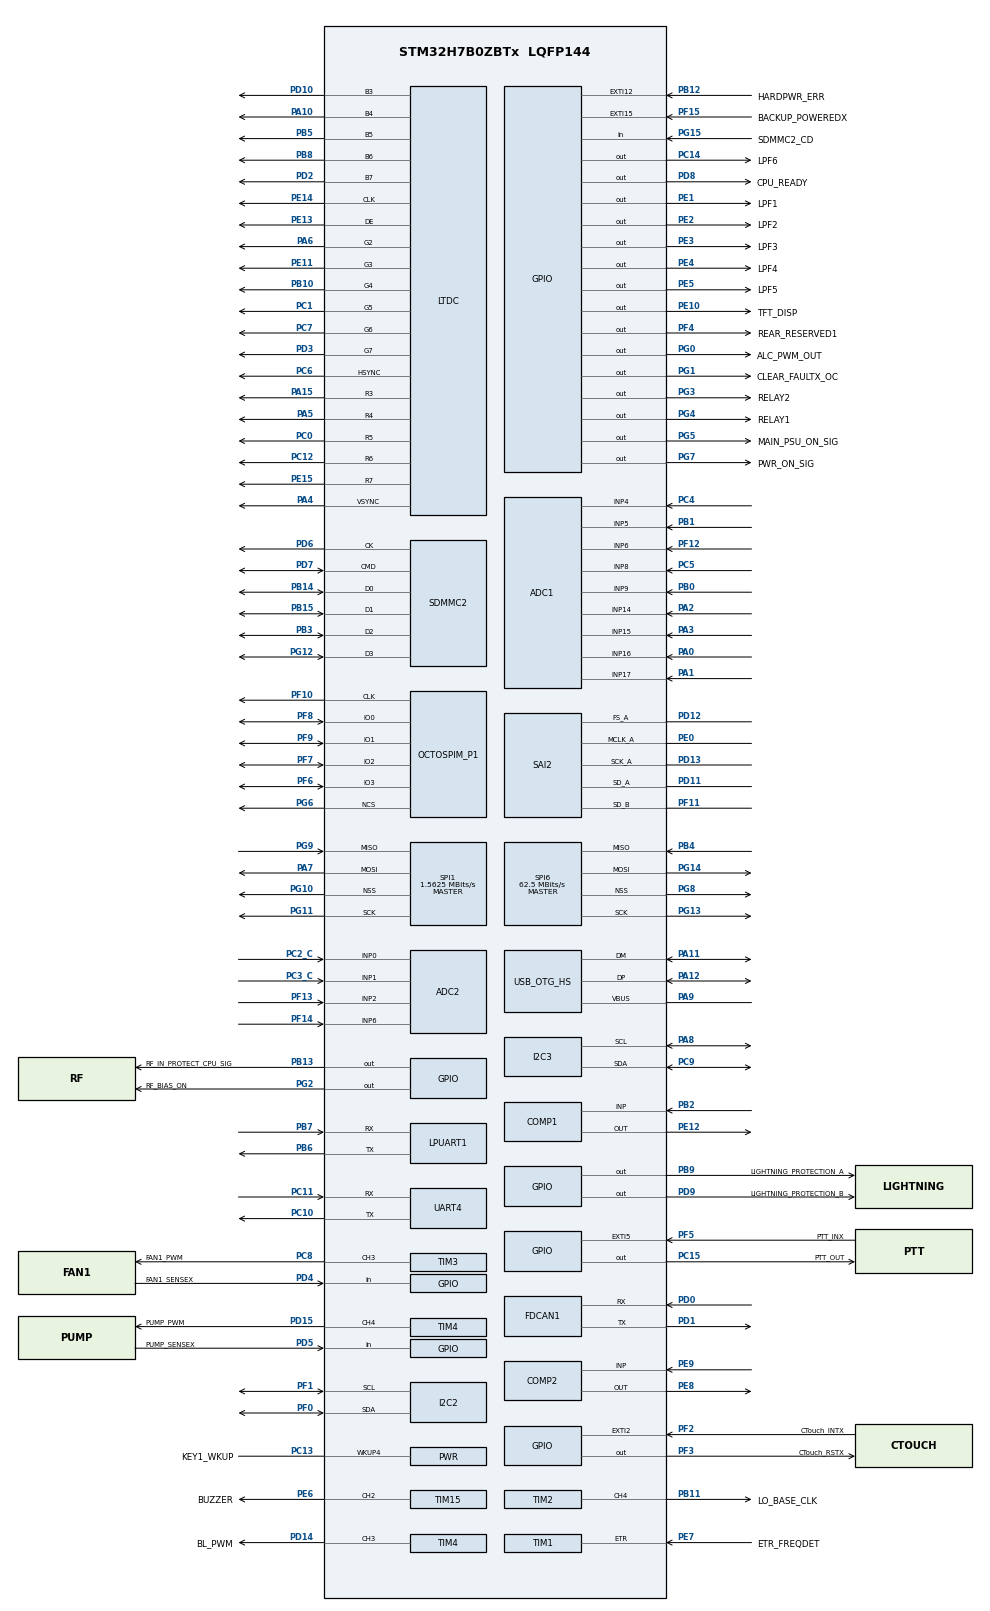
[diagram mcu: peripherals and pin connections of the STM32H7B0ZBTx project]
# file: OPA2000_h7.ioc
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ADC1.AWD1HighThreshold=65532
ADC1.AWD1ITMode=ENABLE
ADC1.AWD2HighThreshold=65532
ADC1.AWD2ITMode=ENABLE
ADC1.AWD3HighThreshold=65532
ADC1.AWD3ITMode=ENABLE
ADC1.AWDChannel-3\#ChannelRegularConversion=ADC_CHANNEL_5
ADC1.AWDChannel-4\#ChannelRegularConversion=ADC_CHANNEL_6
ADC1.Channel-10\#ChannelRegularConversion=ADC_CHANNEL_16
ADC1.Channel-11\#ChannelRegularConversion=ADC_CHANNEL_17
ADC1.Channel-2\#ChannelRegularConversion=ADC_CHANNEL_4
ADC1.Channel-3\#ChannelRegularConversion=ADC_CHANNEL_5
ADC1.Channel-4\#ChannelRegularConversion=ADC_CHANNEL_6
ADC1.Channel-5\#ChannelRegularConversion=ADC_CHANNEL_8
ADC1.Channel-7\#ChannelRegularConversion=ADC_CHANNEL_9
ADC1.Channel-8\#ChannelRegularConversion=ADC_CHANNEL_14
ADC1.Channel-9\#ChannelRegularConversion=ADC_CHANNEL_15
ADC1.ClockPrescaler=ADC_CLOCK_ASYNC_DIV1
ADC1.ContinuousConvMode=ENABLE
ADC1.ConversionDataManagement=ADC_CONVERSIONDATA_DMA_CIRCULAR
ADC1.EOCSelection=ADC_EOC_SEQ_CONV
ADC1.EnableAnalogWatchDog1=true
ADC1.EnableAnalogWatchDog2=true
ADC1.EnableAnalogWatchDog3=true
ADC1.EnableInjectedConversion=DISABLE
ADC1.MonitoredBy-10\#ChannelRegularConversion=__NULL
ADC1.MonitoredBy-11\#ChannelRegularConversion=__NULL
ADC1.MonitoredBy-3\#ChannelRegularConversion=ADC_ANALOGWATCHDOG_2
ADC1.MonitoredBy-4\#ChannelRegularConversion=ADC_ANALOGWATCHDOG_3
ADC1.MonitoredBy-8\#ChannelRegularConversion=__NULL
ADC1.MonitoredBy-9\#ChannelRegularConversion=__NULL
ADC1.NbrOfConversion=9
ADC1.NbrOfConversionFlag=1
ADC1.OffsetNumber-10\#ChannelRegularConversion=ADC_OFFSET_NONE
ADC1.OffsetNumber-11\#ChannelRegularConversion=ADC_OFFSET_NONE
ADC1.OffsetNumber-2\#ChannelRegularConversion=ADC_OFFSET_NONE
ADC1.OffsetNumber-3\#ChannelRegularConversion=ADC_OFFSET_NONE
ADC1.OffsetNumber-4\#ChannelRegularConversion=ADC_OFFSET_NONE
ADC1.OffsetNumber-5\#ChannelRegularConversion=ADC_OFFSET_NONE
ADC1.OffsetNumber-7\#ChannelRegularConversion=ADC_OFFSET_NONE
ADC1.OffsetNumber-8\#ChannelRegularConversion=ADC_OFFSET_NONE
ADC1.OffsetNumber-9\#ChannelRegularConversion=ADC_OFFSET_NONE
ADC1.OffsetSignedSaturation-10\#ChannelRegularConversion=DISABLE
ADC1.OffsetSignedSaturation-11\#ChannelRegularConversion=DISABLE
ADC1.OffsetSignedSaturation-2\#ChannelRegularConversion=DISABLE
ADC1.OffsetSignedSaturation-3\#ChannelRegularConversion=DISABLE
ADC1.OffsetSignedSaturation-4\#ChannelRegularConversion=DISABLE
ADC1.OffsetSignedSaturation-5\#ChannelRegularConversion=DISABLE
ADC1.OffsetSignedSaturation-7\#ChannelRegularConversion=DISABLE
ADC1.OffsetSignedSaturation-8\#ChannelRegularConversion=DISABLE
ADC1.OffsetSignedSaturation-9\#ChannelRegularConversion=DISABLE
ADC1.Overrun=ADC_OVR_DATA_PRESERVED
ADC1.Rank-10\#ChannelRegularConversion=8
ADC1.Rank-11\#ChannelRegularConversion=9
ADC1.Rank-2\#ChannelRegularConversion=1
ADC1.Rank-3\#ChannelRegularConversion=2
ADC1.Rank-4\#ChannelRegularConversion=3
ADC1.Rank-5\#ChannelRegularConversion=4
ADC1.Rank-7\#ChannelRegularConversion=5
ADC1.Rank-8\#ChannelRegularConversion=6
ADC1.Rank-9\#ChannelRegularConversion=7
ADC1.SamplingTime-10\#ChannelRegularConversion=ADC_SAMPLETIME_1CYCLE_5
ADC1.SamplingTime-11\#ChannelRegularConversion=ADC_SAMPLETIME_1CYCLE_5
ADC1.SamplingTime-2\#ChannelRegularConversion=ADC_SAMPLETIME_16CYCLES_5
ADC1.SamplingTime-3\#ChannelRegularConversion=ADC_SAMPLETIME_16CYCLES_5
ADC1.SamplingTime-4\#ChannelRegularConversion=ADC_SAMPLETIME_16CYCLES_5
ADC1.SamplingTime-5\#ChannelRegularConversion=ADC_SAMPLETIME_16CYCLES_5
ADC1.SamplingTime-7\#ChannelRegularConversion=ADC_SAMPLETIME_16CYCLES_5
ADC1.SamplingTime-8\#ChannelRegularConversion=ADC_SAMPLETIME_16CYCLES_5
ADC1.SamplingTime-9\#ChannelRegularConversion=ADC_SAMPLETIME_16CYCLES_5
ADC1.WDG2ChannelR2=ADC_CHANNEL_5
ADC1.WDG3ChannelR3=ADC_CHANNEL_6
ADC1.WatchdogChannel=ADC_CHANNEL_4
ADC1.WatchdogMode=ADC_ANALOGWATCHDOG_SINGLE_REG
ADC1.master=1
ADC2.AWD1HighThreshold=65535
ADC2.AWD1ITMode=ENABLE
ADC2.AWD2HighThreshold=65535
ADC2.AWDChannel-2\#ChannelRegularConversion=ADC_CHANNEL_1
ADC2.Channel-1\#ChannelRegularConversion=ADC_CHANNEL_0
ADC2.Channel-2\#ChannelRegularConversion=ADC_CHANNEL_1
ADC2.ContinuousConvMode=ENABLE
ADC2.ConversionDataManagement=ADC_CONVERSIONDATA_DMA_CIRCULAR
ADC2.EOCSelection=ADC_EOC_SEQ_CONV
ADC2.EnableAnalogWatchDog1=true
ADC2.EnableAnalogWatchDog2=true
ADC2.EnableAnalogWatchDog3=false
ADC2.EnableInjectedConversion=ENABLE
ADC2.InjMonitoredBy-13\#ChannelInjectedConversion=__NULL
ADC2.InjNumberOfConversion=3
ADC2.InjectedChannel-11\#ChannelInjectedConversion=ADC_CHANNEL_2
ADC2.InjectedChannel-12\#ChannelInjectedConversion=ADC_CHANNEL_6
ADC2.InjectedChannel-13\#ChannelInjectedConversion=ADC_CHANNEL_TEMPSENSOR
ADC2.InjectedConvMode=None
ADC2.InjectedOffsetNumber-11\#ChannelInjectedConversion=ADC_OFFSET_NONE
ADC2.InjectedOffsetNumber-12\#ChannelInjectedConversion=ADC_OFFSET_NONE
ADC2.InjectedOffsetNumber-13\#ChannelInjectedConversion=ADC_OFFSET_NONE
ADC2.InjectedRank-11\#ChannelInjectedConversion=1
ADC2.InjectedRank-12\#ChannelInjectedConversion=2
ADC2.InjectedRank-13\#ChannelInjectedConversion=3
ADC2.InjectedSamplingTime-11\#ChannelInjectedConversion=ADC_SAMPLETIME_1CYCLE_5
ADC2.InjectedSamplingTime-12\#ChannelInjectedConversion=ADC_SAMPLETIME_1CYCLE_5
ADC2.InjectedSamplingTime-13\#ChannelInjectedConversion=ADC_SAMPLETIME_1CYCLE_5
ADC2.MonitoredBy-2\#ChannelRegularConversion=ADC_ANALOGWATCHDOG_2
ADC2.NbrOfConversion=2
ADC2.NbrOfConversionFlag=1
ADC2.OffsetNumber-1\#ChannelRegularConversion=ADC_OFFSET_NONE
ADC2.OffsetNumber-2\#ChannelRegularConversion=ADC_OFFSET_NONE
ADC2.OffsetSignedSaturation-1\#ChannelRegularConversion=DISABLE
ADC2.OffsetSignedSaturation-2\#ChannelRegularConversion=DISABLE
ADC2.Overrun=ADC_OVR_DATA_PRESERVED
ADC2.Rank-1\#ChannelRegularConversion=1
ADC2.Rank-2\#ChannelRegularConversion=2
ADC2.SamplingTime-1\#ChannelRegularConversion=ADC_SAMPLETIME_1CYCLE_5
ADC2.SamplingTime-2\#ChannelRegularConversion=ADC_SAMPLETIME_1CYCLE_5
ADC2.WDG2ChannelR2=ADC_CHANNEL_1
ADC2.WatchdogChannel=ADC_CHANNEL_0
ADC2.WatchdogMode=ADC_ANALOGWATCHDOG_SINGLE_REG
ADC2.injectedQueueMode=DISABLE
Bdma2.LPUART1_RX.0.Direction=DMA_PERIPH_TO_MEMORY
Bdma2.LPUART1_RX.0.EventEnable=DISABLE
Bdma2.LPUART1_RX.0.Instance=BDMA2_Channel0
Bdma2.LPUART1_RX.0.MemDataAlignment=DMA_MDATAALIGN_BYTE
Bdma2.LPUART1_RX.0.MemInc=DMA_MINC_ENABLE
Bdma2.LPUART1_RX.0.Mode=DMA_NORMAL
Bdma2.LPUART1_RX.0.PeriphDataAlignment=DMA_PDATAALIGN_BYTE
Bdma2.LPUART1_RX.0.PeriphInc=DMA_PINC_DISABLE
Bdma2.LPUART1_RX.0.Polarity=HAL_DMAMUX_REQ_GEN_RISING
Bdma2.LPUART1_RX.0.Priority=DMA_PRIORITY_LOW
Bdma2.LPUART1_RX.0.RequestNumber=1
Bdma2.LPUART1_RX.0.SignalID=NONE
Bdma2.LPUART1_RX.0.SyncEnable=DISABLE
Bdma2.LPUART1_RX.0.SyncPolarity=HAL_DMAMUX_SYNC_NO_EVENT
Bdma2.LPUART1_RX.0.SyncRequestNumber=1
Bdma2.LPUART1_RX.0.SyncSignalID=NONE
Bdma2.LPUART1_TX.1.Direction=DMA_MEMORY_TO_PERIPH
Bdma2.LPUART1_TX.1.EventEnable=DISABLE
Bdma2.LPUART1_TX.1.Instance=BDMA2_Channel1
Bdma2.LPUART1_TX.1.MemDataAlignment=DMA_MDATAALIGN_BYTE
Bdma2.LPUART1_TX.1.MemInc=DMA_MINC_ENABLE
Bdma2.LPUART1_TX.1.Mode=DMA_NORMAL
Bdma2.LPUART1_TX.1.PeriphDataAlignment=DMA_PDATAALIGN_BYTE
Bdma2.LPUART1_TX.1.PeriphInc=DMA_PINC_DISABLE
Bdma2.LPUART1_TX.1.Polarity=HAL_DMAMUX_REQ_GEN_RISING
Bdma2.LPUART1_TX.1.Priority=DMA_PRIORITY_LOW
Bdma2.LPUART1_TX.1.RequestNumber=1
Bdma2.LPUART1_TX.1.SignalID=NONE
Bdma2.LPUART1_TX.1.SyncEnable=DISABLE
Bdma2.LPUART1_TX.1.SyncPolarity=HAL_DMAMUX_SYNC_NO_EVENT
Bdma2.LPUART1_TX.1.SyncRequestNumber=1
Bdma2.LPUART1_TX.1.SyncSignalID=NONE
Bdma2.Request0=LPUART1_RX
Bdma2.Request1=LPUART1_TX
Bdma2.RequestsNb=2
COMP1.Hysteresis=COMP_HYSTERESIS_HIGH
COMP1.TriggerMode=COMP_TRIGGERMODE_IT_RISING
COMP2.Hysteresis=COMP_HYSTERESIS_HIGH
COMP2.TriggerMode=COMP_TRIGGERMODE_IT_RISING
CORTEX_M7.AccessPermission_S-Cortex_Memory_Protection_Unit_Region1_Settings_S=MPU_REGION_FULL_ACCESS
CORTEX_M7.AccessPermission_S-Cortex_Memory_Protection_Unit_Region2_Settings_S=MPU_REGION_FULL_ACCESS
CORTEX_M7.AccessPermission_S-Cortex_Memory_Protection_Unit_Region3_Settings_S=MPU_REGION_FULL_ACCESS
CORTEX_M7.AccessPermission_S-Cortex_Memory_Protection_Unit_Region4_Settings_S=MPU_REGION_FULL_ACCESS
CORTEX_M7.AccessPermission_S-Cortex_Memory_Protection_Unit_Region5_Settings_S=MPU_REGION_FULL_ACCESS
CORTEX_M7.AccessPermission_S-Cortex_Memory_Protection_Unit_Region6_Settings_S=MPU_REGION_FULL_ACCESS
CORTEX_M7.AccessPermission_Spec=MPU_REGION_FULL_ACCESS
CORTEX_M7.BaseAddress_S-Cortex_Memory_Protection_Unit_Region1_Settings_S=0x90000000
CORTEX_M7.BaseAddress_S-Cortex_Memory_Protection_Unit_Region2_Settings_S=0x20000000
CORTEX_M7.BaseAddress_S-Cortex_Memory_Protection_Unit_Region3_Settings_S=0x24000000
CORTEX_M7.BaseAddress_S-Cortex_Memory_Protection_Unit_Region4_Settings_S=0x24000000
CORTEX_M7.BaseAddress_S-Cortex_Memory_Protection_Unit_Region5_Settings_S=0x30000000
CORTEX_M7.BaseAddress_S-Cortex_Memory_Protection_Unit_Region6_Settings_S=0x38000000
CORTEX_M7.BaseAddress_Spec=0x08000000
CORTEX_M7.CPU_DCache=Enabled
CORTEX_M7.CPU_ICache=Enabled
CORTEX_M7.DisableExec_S-Cortex_Memory_Protection_Unit_Region4_Settings_S=MPU_INSTRUCTION_ACCESS_ENABLE
CORTEX_M7.DisableExec_Spec=MPU_INSTRUCTION_ACCESS_ENABLE
CORTEX_M7.Enable_S-Cortex_Memory_Protection_Unit_Region1_Settings_S=MPU_REGION_ENABLE
CORTEX_M7.Enable_S-Cortex_Memory_Protection_Unit_Region2_Settings_S=MPU_REGION_ENABLE
CORTEX_M7.Enable_S-Cortex_Memory_Protection_Unit_Region3_Settings_S=MPU_REGION_ENABLE
CORTEX_M7.Enable_S-Cortex_Memory_Protection_Unit_Region4_Settings_S=MPU_REGION_ENABLE
CORTEX_M7.Enable_S-Cortex_Memory_Protection_Unit_Region5_Settings_S=MPU_REGION_ENABLE
CORTEX_M7.Enable_S-Cortex_Memory_Protection_Unit_Region6_Settings_S=MPU_REGION_ENABLE
CORTEX_M7.Enable_S-Cortex_Memory_Protection_Unit_Region7_Settings_S=__NULL
CORTEX_M7.Enable_S-Cortex_Memory_Protection_Unit_Region8_Settings_S=__NULL
CORTEX_M7.IsBufferable_S-Cortex_Memory_Protection_Unit_Region1_Settings_S=MPU_ACCESS_BUFFERABLE
CORTEX_M7.IsBufferable_S-Cortex_Memory_Protection_Unit_Region2_Settings_S=MPU_ACCESS_NOT_BUFFERABLE
CORTEX_M7.IsBufferable_S-Cortex_Memory_Protection_Unit_Region3_Settings_S=MPU_ACCESS_BUFFERABLE
CORTEX_M7.IsBufferable_S-Cortex_Memory_Protection_Unit_Region4_Settings_S=MPU_ACCESS_NOT_BUFFERABLE
CORTEX_M7.IsBufferable_S-Cortex_Memory_Protection_Unit_Region5_Settings_S=MPU_ACCESS_BUFFERABLE
CORTEX_M7.IsBufferable_S-Cortex_Memory_Protection_Unit_Region6_Settings_S=MPU_ACCESS_NOT_BUFFERABLE
CORTEX_M7.IsBufferable_Spec=MPU_ACCESS_BUFFERABLE
CORTEX_M7.IsCacheable_S-Cortex_Memory_Protection_Unit_Region1_Settings_S=MPU_ACCESS_CACHEABLE
CORTEX_M7.IsCacheable_S-Cortex_Memory_Protection_Unit_Region2_Settings_S=MPU_ACCESS_NOT_CACHEABLE
CORTEX_M7.IsCacheable_S-Cortex_Memory_Protection_Unit_Region3_Settings_S=MPU_ACCESS_CACHEABLE
CORTEX_M7.IsCacheable_S-Cortex_Memory_Protection_Unit_Region4_Settings_S=MPU_ACCESS_NOT_CACHEABLE
CORTEX_M7.IsCacheable_S-Cortex_Memory_Protection_Unit_Region5_Settings_S=MPU_ACCESS_CACHEABLE
CORTEX_M7.IsCacheable_S-Cortex_Memory_Protection_Unit_Region6_Settings_S=MPU_ACCESS_NOT_CACHEABLE
CORTEX_M7.IsCacheable_Spec=MPU_ACCESS_CACHEABLE
CORTEX_M7.IsShareable_S-Cortex_Memory_Protection_Unit_Region3_Settings_S=MPU_ACCESS_NOT_SHAREABLE
CORTEX_M7.IsShareable_S-Cortex_Memory_Protection_Unit_Region5_Settings_S=MPU_ACCESS_NOT_SHAREABLE
CORTEX_M7.IsShareable_S-Cortex_Memory_Protection_Unit_Region6_Settings_S=MPU_ACCESS_NOT_SHAREABLE
CORTEX_M7.IsShareable_Spec=MPU_ACCESS_NOT_SHAREABLE
CORTEX_M7.Size_S-Cortex_Memory_Protection_Unit_Region1_Settings_S=MPU_REGION_SIZE_128MB
CORTEX_M7.Size_S-Cortex_Memory_Protection_Unit_Region2_Settings_S=MPU_REGION_SIZE_128KB
CORTEX_M7.Size_S-Cortex_Memory_Protection_Unit_Region3_Settings_S=MPU_REGION_SIZE_1MB
CORTEX_M7.Size_S-Cortex_Memory_Protection_Unit_Region4_Settings_S=MPU_REGION_SIZE_512KB
CORTEX_M7.Size_S-Cortex_Memory_Protection_Unit_Region5_Settings_S=MPU_REGION_SIZE_128KB
CORTEX_M7.Size_S-Cortex_Memory_Protection_Unit_Region6_Settings_S=MPU_REGION_SIZE_32KB
CORTEX_M7.Size_Spec=MPU_REGION_SIZE_256KB
CORTEX_M7.SubRegionDisable_Spec=0
CORTEX_M7.default_mode_Activation=1
DAC1.DAC_Channel-DAC_OUT1_Int=DAC_CHANNEL_1
DAC1.DAC_Channel-DAC_OUT2_Int=DAC_CHANNEL_2
DAC1.DAC_SampleAndHold-DAC_OUT2_Int=DAC_SAMPLEANDHOLD_DISABLE
DAC2.DAC1_OutputBuffer-DAC_OUT1=DAC_OUTPUTBUFFER_DISABLE
DAC2.DAC_Channel-DAC_OUT1_Int=DAC_CHANNEL_1
DAC2.DAC_Channel-DAC_OUT2_Int=DAC_CHANNEL_2
DAC2.DAC_SampleAndHold-DAC_OUT1=DAC_SAMPLEANDHOLD_ENABLE
DMA2D.ColorMode=DMA2D_OUTPUT_RGB565
Dma.ADC1.4.Direction=DMA_PERIPH_TO_MEMORY
Dma.ADC1.4.EventEnable=DISABLE
Dma.ADC1.4.FIFOMode=DMA_FIFOMODE_ENABLE
Dma.ADC1.4.FIFOThreshold=DMA_FIFO_THRESHOLD_HALFFULL
Dma.ADC1.4.Instance=DMA2_Stream2
Dma.ADC1.4.MemBurst=DMA_MBURST_INC4
Dma.ADC1.4.MemDataAlignment=DMA_MDATAALIGN_HALFWORD
Dma.ADC1.4.MemInc=DMA_MINC_ENABLE
Dma.ADC1.4.Mode=DMA_CIRCULAR
Dma.ADC1.4.PeriphBurst=DMA_PBURST_INC4
Dma.ADC1.4.PeriphDataAlignment=DMA_PDATAALIGN_HALFWORD
Dma.ADC1.4.PeriphInc=DMA_PINC_DISABLE
Dma.ADC1.4.Polarity=HAL_DMAMUX_REQ_GEN_RISING
Dma.ADC1.4.Priority=DMA_PRIORITY_HIGH
Dma.ADC1.4.RequestNumber=1
Dma.ADC1.4.SignalID=NONE
Dma.ADC1.4.SyncEnable=DISABLE
Dma.ADC1.4.SyncPolarity=HAL_DMAMUX_SYNC_NO_EVENT
Dma.ADC1.4.SyncRequestNumber=1
Dma.ADC1.4.SyncSignalID=NONE
Dma.ADC2.5.Direction=DMA_PERIPH_TO_MEMORY
Dma.ADC2.5.EventEnable=DISABLE
Dma.ADC2.5.FIFOMode=DMA_FIFOMODE_ENABLE
Dma.ADC2.5.FIFOThreshold=DMA_FIFO_THRESHOLD_HALFFULL
Dma.ADC2.5.Instance=DMA1_Stream7
Dma.ADC2.5.MemBurst=DMA_MBURST_INC4
Dma.ADC2.5.MemDataAlignment=DMA_MDATAALIGN_HALFWORD
Dma.ADC2.5.MemInc=DMA_MINC_ENABLE
Dma.ADC2.5.Mode=DMA_CIRCULAR
Dma.ADC2.5.PeriphBurst=DMA_PBURST_INC4
Dma.ADC2.5.PeriphDataAlignment=DMA_PDATAALIGN_HALFWORD
Dma.ADC2.5.PeriphInc=DMA_PINC_DISABLE
Dma.ADC2.5.Polarity=HAL_DMAMUX_REQ_GEN_RISING
Dma.ADC2.5.Priority=DMA_PRIORITY_HIGH
Dma.ADC2.5.RequestNumber=1
Dma.ADC2.5.SignalID=NONE
Dma.ADC2.5.SyncEnable=DISABLE
Dma.ADC2.5.SyncPolarity=HAL_DMAMUX_SYNC_NO_EVENT
Dma.ADC2.5.SyncRequestNumber=1
Dma.ADC2.5.SyncSignalID=NONE
Dma.I2C2_RX.12.Direction=DMA_PERIPH_TO_MEMORY
Dma.I2C2_RX.12.EventEnable=DISABLE
Dma.I2C2_RX.12.FIFOMode=DMA_FIFOMODE_DISABLE
Dma.I2C2_RX.12.Instance=DMA2_Stream7
Dma.I2C2_RX.12.MemDataAlignment=DMA_MDATAALIGN_BYTE
Dma.I2C2_RX.12.MemInc=DMA_MINC_ENABLE
Dma.I2C2_RX.12.Mode=DMA_NORMAL
Dma.I2C2_RX.12.PeriphDataAlignment=DMA_PDATAALIGN_BYTE
Dma.I2C2_RX.12.PeriphInc=DMA_PINC_DISABLE
Dma.I2C2_RX.12.Polarity=HAL_DMAMUX_REQ_GEN_RISING
Dma.I2C2_RX.12.Priority=DMA_PRIORITY_LOW
Dma.I2C2_RX.12.RequestNumber=1
Dma.I2C2_RX.12.SignalID=NONE
Dma.I2C2_RX.12.SyncEnable=DISABLE
Dma.I2C2_RX.12.SyncPolarity=HAL_DMAMUX_SYNC_NO_EVENT
Dma.I2C2_RX.12.SyncRequestNumber=1
Dma.I2C2_RX.12.SyncSignalID=NONE
Dma.I2C2_TX.13.Direction=DMA_MEMORY_TO_PERIPH
Dma.I2C2_TX.13.EventEnable=DISABLE
Dma.I2C2_TX.13.FIFOMode=DMA_FIFOMODE_DISABLE
Dma.I2C2_TX.13.Instance=DMA2_Stream6
Dma.I2C2_TX.13.MemDataAlignment=DMA_MDATAALIGN_BYTE
Dma.I2C2_TX.13.MemInc=DMA_MINC_ENABLE
Dma.I2C2_TX.13.Mode=DMA_NORMAL
Dma.I2C2_TX.13.PeriphDataAlignment=DMA_PDATAALIGN_BYTE
Dma.I2C2_TX.13.PeriphInc=DMA_PINC_DISABLE
Dma.I2C2_TX.13.Polarity=HAL_DMAMUX_REQ_GEN_RISING
Dma.I2C2_TX.13.Priority=DMA_PRIORITY_LOW
Dma.I2C2_TX.13.RequestNumber=1
Dma.I2C2_TX.13.SignalID=NONE
Dma.I2C2_TX.13.SyncEnable=DISABLE
Dma.I2C2_TX.13.SyncPolarity=HAL_DMAMUX_SYNC_NO_EVENT
Dma.I2C2_TX.13.SyncRequestNumber=1
Dma.I2C2_TX.13.SyncSignalID=NONE
Dma.I2C3_RX.2.Direction=DMA_PERIPH_TO_MEMORY
Dma.I2C3_RX.2.EventEnable=DISABLE
Dma.I2C3_RX.2.FIFOMode=DMA_FIFOMODE_DISABLE
Dma.I2C3_RX.2.Instance=DMA1_Stream2
Dma.I2C3_RX.2.MemDataAlignment=DMA_MDATAALIGN_BYTE
Dma.I2C3_RX.2.MemInc=DMA_MINC_ENABLE
Dma.I2C3_RX.2.Mode=DMA_NORMAL
Dma.I2C3_RX.2.PeriphDataAlignment=DMA_PDATAALIGN_BYTE
Dma.I2C3_RX.2.PeriphInc=DMA_PINC_DISABLE
Dma.I2C3_RX.2.Polarity=HAL_DMAMUX_REQ_GEN_RISING
Dma.I2C3_RX.2.Priority=DMA_PRIORITY_LOW
Dma.I2C3_RX.2.RequestNumber=1
Dma.I2C3_RX.2.SignalID=NONE
Dma.I2C3_RX.2.SyncEnable=DISABLE
Dma.I2C3_RX.2.SyncPolarity=HAL_DMAMUX_SYNC_NO_EVENT
Dma.I2C3_RX.2.SyncRequestNumber=1
Dma.I2C3_RX.2.SyncSignalID=NONE
Dma.I2C3_TX.3.Direction=DMA_MEMORY_TO_PERIPH
Dma.I2C3_TX.3.EventEnable=DISABLE
Dma.I2C3_TX.3.FIFOMode=DMA_FIFOMODE_DISABLE
Dma.I2C3_TX.3.Instance=DMA1_Stream3
Dma.I2C3_TX.3.MemDataAlignment=DMA_MDATAALIGN_BYTE
Dma.I2C3_TX.3.MemInc=DMA_MINC_ENABLE
Dma.I2C3_TX.3.Mode=DMA_NORMAL
Dma.I2C3_TX.3.PeriphDataAlignment=DMA_PDATAALIGN_BYTE
Dma.I2C3_TX.3.PeriphInc=DMA_PINC_DISABLE
Dma.I2C3_TX.3.Polarity=HAL_DMAMUX_REQ_GEN_RISING
Dma.I2C3_TX.3.Priority=DMA_PRIORITY_LOW
Dma.I2C3_TX.3.RequestNumber=1
Dma.I2C3_TX.3.SignalID=NONE
Dma.I2C3_TX.3.SyncEnable=DISABLE
Dma.I2C3_TX.3.SyncPolarity=HAL_DMAMUX_SYNC_NO_EVENT
Dma.I2C3_TX.3.SyncRequestNumber=1
Dma.I2C3_TX.3.SyncSignalID=NONE
Dma.Request0=SPI1_RX
Dma.Request1=SPI1_TX
Dma.Request10=SAI2_A
Dma.Request11=SAI2_B
Dma.Request12=I2C2_RX
Dma.Request13=I2C2_TX
Dma.Request2=I2C3_RX
Dma.Request3=I2C3_TX
Dma.Request4=ADC1
Dma.Request5=ADC2
Dma.Request6=TIM2_CH1
Dma.Request7=TIM2_CH2
Dma.Request8=UART4_RX
Dma.Request9=UART4_TX
Dma.SAI2_A.10.Direction=DMA_MEMORY_TO_PERIPH
Dma.SAI2_A.10.EventEnable=DISABLE
Dma.SAI2_A.10.FIFOMode=DMA_FIFOMODE_DISABLE
Dma.SAI2_A.10.Instance=DMA1_Stream4
Dma.SAI2_A.10.MemDataAlignment=DMA_MDATAALIGN_WORD
Dma.SAI2_A.10.MemInc=DMA_MINC_ENABLE
Dma.SAI2_A.10.Mode=DMA_CIRCULAR
Dma.SAI2_A.10.PeriphDataAlignment=DMA_PDATAALIGN_WORD
Dma.SAI2_A.10.PeriphInc=DMA_PINC_DISABLE
Dma.SAI2_A.10.Polarity=HAL_DMAMUX_REQ_GEN_RISING
Dma.SAI2_A.10.Priority=DMA_PRIORITY_LOW
Dma.SAI2_A.10.RequestNumber=1
Dma.SAI2_A.10.SignalID=NONE
Dma.SAI2_A.10.SyncEnable=DISABLE
Dma.SAI2_A.10.SyncPolarity=HAL_DMAMUX_SYNC_NO_EVENT
Dma.SAI2_A.10.SyncRequestNumber=1
Dma.SAI2_A.10.SyncSignalID=NONE
Dma.SAI2_B.11.Direction=DMA_PERIPH_TO_MEMORY
Dma.SAI2_B.11.EventEnable=DISABLE
Dma.SAI2_B.11.FIFOMode=DMA_FIFOMODE_DISABLE
Dma.SAI2_B.11.Instance=DMA1_Stream5
Dma.SAI2_B.11.MemDataAlignment=DMA_MDATAALIGN_WORD
Dma.SAI2_B.11.MemInc=DMA_MINC_ENABLE
Dma.SAI2_B.11.Mode=DMA_CIRCULAR
Dma.SAI2_B.11.PeriphDataAlignment=DMA_PDATAALIGN_WORD
Dma.SAI2_B.11.PeriphInc=DMA_PINC_DISABLE
Dma.SAI2_B.11.Polarity=HAL_DMAMUX_REQ_GEN_RISING
Dma.SAI2_B.11.Priority=DMA_PRIORITY_LOW
Dma.SAI2_B.11.RequestNumber=1
Dma.SAI2_B.11.SignalID=NONE
Dma.SAI2_B.11.SyncEnable=DISABLE
Dma.SAI2_B.11.SyncPolarity=HAL_DMAMUX_SYNC_NO_EVENT
Dma.SAI2_B.11.SyncRequestNumber=1
Dma.SAI2_B.11.SyncSignalID=NONE
Dma.SPI1_RX.0.Direction=DMA_PERIPH_TO_MEMORY
Dma.SPI1_RX.0.EventEnable=DISABLE
Dma.SPI1_RX.0.FIFOMode=DMA_FIFOMODE_DISABLE
Dma.SPI1_RX.0.Instance=DMA1_Stream0
Dma.SPI1_RX.0.MemDataAlignment=DMA_MDATAALIGN_BYTE
Dma.SPI1_RX.0.MemInc=DMA_MINC_ENABLE
Dma.SPI1_RX.0.Mode=DMA_NORMAL
Dma.SPI1_RX.0.PeriphDataAlignment=DMA_PDATAALIGN_BYTE
Dma.SPI1_RX.0.PeriphInc=DMA_PINC_DISABLE
Dma.SPI1_RX.0.Polarity=HAL_DMAMUX_REQ_GEN_RISING
Dma.SPI1_RX.0.Priority=DMA_PRIORITY_MEDIUM
Dma.SPI1_RX.0.RequestNumber=1
Dma.SPI1_RX.0.SignalID=NONE
Dma.SPI1_RX.0.SyncEnable=DISABLE
Dma.SPI1_RX.0.SyncPolarity=HAL_DMAMUX_SYNC_NO_EVENT
Dma.SPI1_RX.0.SyncRequestNumber=1
Dma.SPI1_RX.0.SyncSignalID=NONE
Dma.SPI1_TX.1.Direction=DMA_MEMORY_TO_PERIPH
Dma.SPI1_TX.1.EventEnable=DISABLE
Dma.SPI1_TX.1.FIFOMode=DMA_FIFOMODE_DISABLE
Dma.SPI1_TX.1.Instance=DMA1_Stream1
Dma.SPI1_TX.1.MemDataAlignment=DMA_MDATAALIGN_BYTE
Dma.SPI1_TX.1.MemInc=DMA_MINC_ENABLE
Dma.SPI1_TX.1.Mode=DMA_NORMAL
Dma.SPI1_TX.1.PeriphDataAlignment=DMA_PDATAALIGN_BYTE
Dma.SPI1_TX.1.PeriphInc=DMA_PINC_DISABLE
Dma.SPI1_TX.1.Polarity=HAL_DMAMUX_REQ_GEN_RISING
Dma.SPI1_TX.1.Priority=DMA_PRIORITY_MEDIUM
Dma.SPI1_TX.1.RequestNumber=1
Dma.SPI1_TX.1.SignalID=NONE
Dma.SPI1_TX.1.SyncEnable=DISABLE
Dma.SPI1_TX.1.SyncPolarity=HAL_DMAMUX_SYNC_NO_EVENT
Dma.SPI1_TX.1.SyncRequestNumber=1
Dma.SPI1_TX.1.SyncSignalID=NONE
Dma.TIM2_CH1.6.Direction=DMA_MEMORY_TO_PERIPH
Dma.TIM2_CH1.6.EventEnable=DISABLE
Dma.TIM2_CH1.6.FIFOMode=DMA_FIFOMODE_DISABLE
Dma.TIM2_CH1.6.Instance=DMA2_Stream0
Dma.TIM2_CH1.6.MemDataAlignment=DMA_MDATAALIGN_WORD
Dma.TIM2_CH1.6.MemInc=DMA_MINC_DISABLE
Dma.TIM2_CH1.6.Mode=DMA_CIRCULAR
Dma.TIM2_CH1.6.PeriphDataAlignment=DMA_PDATAALIGN_WORD
Dma.TIM2_CH1.6.PeriphInc=DMA_PINC_DISABLE
Dma.TIM2_CH1.6.Polarity=HAL_DMAMUX_REQ_GEN_RISING
Dma.TIM2_CH1.6.Priority=DMA_PRIORITY_VERY_HIGH
Dma.TIM2_CH1.6.RequestNumber=1
Dma.TIM2_CH1.6.SignalID=NONE
Dma.TIM2_CH1.6.SyncEnable=DISABLE
Dma.TIM2_CH1.6.SyncPolarity=HAL_DMAMUX_SYNC_NO_EVENT
Dma.TIM2_CH1.6.SyncRequestNumber=1
Dma.TIM2_CH1.6.SyncSignalID=NONE
Dma.TIM2_CH2.7.Direction=DMA_MEMORY_TO_PERIPH
Dma.TIM2_CH2.7.EventEnable=DISABLE
Dma.TIM2_CH2.7.FIFOMode=DMA_FIFOMODE_DISABLE
Dma.TIM2_CH2.7.Instance=DMA2_Stream1
Dma.TIM2_CH2.7.MemDataAlignment=DMA_MDATAALIGN_WORD
Dma.TIM2_CH2.7.MemInc=DMA_MINC_DISABLE
Dma.TIM2_CH2.7.Mode=DMA_CIRCULAR
Dma.TIM2_CH2.7.PeriphDataAlignment=DMA_PDATAALIGN_WORD
Dma.TIM2_CH2.7.PeriphInc=DMA_PINC_DISABLE
Dma.TIM2_CH2.7.Polarity=HAL_DMAMUX_REQ_GEN_RISING
Dma.TIM2_CH2.7.Priority=DMA_PRIORITY_HIGH
Dma.TIM2_CH2.7.RequestNumber=1
Dma.TIM2_CH2.7.SignalID=NONE
Dma.TIM2_CH2.7.SyncEnable=DISABLE
Dma.TIM2_CH2.7.SyncPolarity=HAL_DMAMUX_SYNC_NO_EVENT
Dma.TIM2_CH2.7.SyncRequestNumber=1
Dma.TIM2_CH2.7.SyncSignalID=NONE
Dma.UART4_RX.8.Direction=DMA_PERIPH_TO_MEMORY
Dma.UART4_RX.8.EventEnable=DISABLE
Dma.UART4_RX.8.FIFOMode=DMA_FIFOMODE_DISABLE
Dma.UART4_RX.8.Instance=DMA1_Stream6
Dma.UART4_RX.8.MemDataAlignment=DMA_MDATAALIGN_BYTE
Dma.UART4_RX.8.MemInc=DMA_MINC_ENABLE
Dma.UART4_RX.8.Mode=DMA_NORMAL
Dma.UART4_RX.8.PeriphDataAlignment=DMA_PDATAALIGN_BYTE
Dma.UART4_RX.8.PeriphInc=DMA_PINC_DISABLE
Dma.UART4_RX.8.Polarity=HAL_DMAMUX_REQ_GEN_RISING
Dma.UART4_RX.8.Priority=DMA_PRIORITY_LOW
Dma.UART4_RX.8.RequestNumber=1
Dma.UART4_RX.8.SignalID=NONE
Dma.UART4_RX.8.SyncEnable=DISABLE
Dma.UART4_RX.8.SyncPolarity=HAL_DMAMUX_SYNC_NO_EVENT
Dma.UART4_RX.8.SyncRequestNumber=1
Dma.UART4_RX.8.SyncSignalID=NONE
Dma.UART4_TX.9.Direction=DMA_MEMORY_TO_PERIPH
Dma.UART4_TX.9.EventEnable=DISABLE
Dma.UART4_TX.9.FIFOMode=DMA_FIFOMODE_ENABLE
Dma.UART4_TX.9.FIFOThreshold=DMA_FIFO_THRESHOLD_HALFFULL
Dma.UART4_TX.9.Instance=DMA2_Stream3
Dma.UART4_TX.9.MemBurst=DMA_MBURST_SINGLE
Dma.UART4_TX.9.MemDataAlignment=DMA_MDATAALIGN_BYTE
Dma.UART4_TX.9.MemInc=DMA_MINC_ENABLE
Dma.UART4_TX.9.Mode=DMA_NORMAL
Dma.UART4_TX.9.PeriphBurst=DMA_PBURST_SINGLE
Dma.UART4_TX.9.PeriphDataAlignment=DMA_PDATAALIGN_BYTE
Dma.UART4_TX.9.PeriphInc=DMA_PINC_DISABLE
Dma.UART4_TX.9.Polarity=HAL_DMAMUX_REQ_GEN_RISING
Dma.UART4_TX.9.Priority=DMA_PRIORITY_LOW
Dma.UART4_TX.9.RequestNumber=1
Dma.UART4_TX.9.SignalID=NONE
Dma.UART4_TX.9.SyncEnable=DISABLE
Dma.UART4_TX.9.SyncPolarity=HAL_DMAMUX_SYNC_NO_EVENT
Dma.UART4_TX.9.SyncRequestNumber=1
Dma.UART4_TX.9.SyncSignalID=NONE
FDCAN1.AutoRetransmission=ENABLE
FDCAN1.CalculateBaudRateNominal=125000
FDCAN1.CalculateTimeBitNominal=8000
FDCAN1.CalculateTimeQuantumNominal=400.0
FDCAN1.ClockCalibrationCCU=DISABLE
FDCAN1.NominalPrescaler=10
FDCAN1.NominalTimeSeg1=14
FDCAN1.NominalTimeSeg2=5
FREERTOS.Tasks01=defaultTask,24,128,StartDefaultTask,Default,NULL,Dynamic,NULL,NULL
I2C2.Timing=0x20A0A3F6
I2C3.Timing=0x20A0A3F6
LTDC.ActiveH=272
LTDC.ActiveW=480
LTDC.Alpha_L0=255
LTDC.Blue=255
LTDC.FBStartAdress_L0=0x24000000
LTDC.Green=200
LTDC.HBP=40
LTDC.HFP=5
LTDC.HSync=5
LTDC.ImageHeight_L0=272
LTDC.ImageWidth_L0=480
LTDC.Layers=0
LTDC.PixelFormat_L0=LTDC_PIXEL_FORMAT_RGB565
LTDC.Red=200
LTDC.VBP=8
LTDC.VFP=8
LTDC.VSync=5
LTDC.WindowX1_L0=480
LTDC.WindowY1_L0=272
Mcu.Family=STM32H7
Mcu.Name=STM32H7B0ZBTx
Mcu.Package=LQFP144
NVIC.ADC_IRQn=true\:0\:0\:true\:false\:true\:false\:true\:true\:true
NVIC.BDMA2_Channel0_IRQn=true\:5\:0\:false\:false\:true\:true\:false\:true\:true
NVIC.BDMA2_Channel1_IRQn=true\:5\:0\:false\:false\:true\:true\:false\:true\:true
NVIC.COMP_IRQn=true\:0\:0\:true\:false\:true\:false\:false\:true\:true
NVIC.DMA1_Stream0_IRQn=true\:5\:0\:false\:false\:true\:true\:false\:true\:true
NVIC.DMA1_Stream1_IRQn=true\:5\:0\:false\:false\:true\:true\:false\:true\:true
NVIC.DMA1_Stream2_IRQn=true\:5\:0\:true\:false\:true\:true\:false\:true\:true
NVIC.DMA1_Stream3_IRQn=true\:5\:0\:false\:false\:true\:true\:false\:true\:true
NVIC.DMA1_Stream4_IRQn=true\:5\:0\:false\:false\:true\:true\:false\:true\:true
NVIC.DMA1_Stream5_IRQn=true\:5\:0\:false\:false\:true\:true\:false\:true\:true
NVIC.DMA1_Stream6_IRQn=true\:5\:0\:false\:false\:true\:false\:false\:true\:true
NVIC.DMA1_Stream7_IRQn=true\:5\:0\:false\:false\:true\:false\:false\:true\:true
NVIC.DMA2D_IRQn=true\:1\:0\:true\:false\:true\:false\:true\:true\:true
NVIC.DMA2_Stream0_IRQn=true\:5\:0\:false\:false\:true\:false\:false\:true\:true
NVIC.DMA2_Stream1_IRQn=true\:5\:0\:false\:false\:true\:false\:false\:true\:true
NVIC.DMA2_Stream2_IRQn=true\:5\:0\:false\:false\:true\:true\:false\:true\:true
NVIC.DMA2_Stream3_IRQn=true\:5\:0\:false\:false\:true\:true\:false\:true\:true
NVIC.DMA2_Stream6_IRQn=true\:5\:0\:false\:false\:true\:false\:false\:true\:true
NVIC.DMA2_Stream7_IRQn=true\:5\:0\:false\:false\:true\:true\:false\:true\:true
NVIC.EXTI15_10_IRQn=true\:0\:0\:true\:false\:true\:false\:true\:true\:true
NVIC.EXTI2_IRQn=true\:5\:0\:false\:false\:true\:true\:true\:true\:true
NVIC.EXTI9_5_IRQn=true\:5\:0\:false\:false\:true\:false\:true\:true\:true
NVIC.I2C2_ER_IRQn=true\:5\:0\:false\:false\:true\:true\:true\:true\:true
NVIC.I2C2_EV_IRQn=true\:5\:0\:false\:false\:true\:true\:true\:true\:true
NVIC.I2C3_ER_IRQn=true\:5\:0\:false\:false\:true\:true\:true\:true\:true
NVIC.I2C3_EV_IRQn=true\:5\:0\:false\:false\:true\:true\:true\:true\:true
NVIC.LPUART1_IRQn=true\:5\:0\:false\:false\:true\:true\:true\:true\:true
NVIC.LTDC_ER_IRQn=true\:5\:0\:false\:false\:true\:true\:true\:true\:true
NVIC.LTDC_IRQn=true\:5\:0\:false\:false\:true\:true\:true\:true\:true
NVIC.OTG_HS_EP1_IN_IRQn=true\:5\:0\:false\:false\:true\:true\:false\:true\:true
NVIC.OTG_HS_EP1_OUT_IRQn=true\:5\:0\:false\:false\:true\:true\:false\:true\:true
NVIC.OTG_HS_IRQn=true\:5\:0\:false\:false\:true\:true\:true\:true\:true
NVIC.PriorityGroup=NVIC_PRIORITYGROUP_4
NVIC.SDMMC2_IRQn=true\:5\:0\:false\:false\:true\:true\:true\:true\:true
NVIC.SPI1_IRQn=true\:5\:0\:false\:false\:true\:true\:false\:true\:true
NVIC.TIM17_IRQn=true\:15\:0\:false\:false\:true\:false\:false\:true\:true
NVIC.TIM1_UP_IRQn=true\:5\:0\:false\:false\:true\:true\:true\:true\:true
NVIC.TIM2_IRQn=true\:1\:0\:true\:false\:true\:false\:true\:true\:true
NVIC.TIM5_IRQn=true\:1\:0\:true\:false\:true\:false\:true\:true\:true
NVIC.TIM7_IRQn=true\:2\:0\:true\:false\:true\:false\:true\:true\:true
NVIC.TimeBase=TIM17_IRQn
NVIC.TimeBaseIP=TIM17
NVIC.UART4_IRQn=true\:5\:0\:false\:false\:true\:true\:true\:true\:true
PA0.Mode=IN16-Single-Ended
PA0.Signal=ADC1_INP16
PA1.Mode=IN17-Single-Ended
PA1.Signal=ADC1_INP17
PA10.Mode=RGB565
PA10.Signal=LTDC_B4
PA11.Mode=Device_Only_FS
PA11.Signal=USB_OTG_HS_DM
PA12.Mode=Device_Only_FS
PA12.Signal=USB_OTG_HS_DP
PA13.Mode=Serial_Wire
PA13.Signal=DEBUG_JTMS-SWDIO
PA14.Mode=Serial_Wire
PA14.Signal=DEBUG_JTCK-SWCLK
PA15.GPIO_Speed=GPIO_SPEED_FREQ_HIGH
PA15.Mode=RGB565
PA15.Signal=LTDC_R3
PA2.Signal=ADCx_INP14
PA3.Mode=IN15-Single-Ended
PA3.Signal=ADC1_INP15
PA4.Mode=RGB565
PA4.Signal=LTDC_VSYNC
PA5.GPIO_Speed=GPIO_SPEED_FREQ_HIGH
PA5.Mode=RGB565
PA5.Signal=LTDC_R4
PA6.GPIO_Speed=GPIO_SPEED_FREQ_HIGH
PA6.Mode=RGB565
PA6.Signal=LTDC_G2
PA7.Mode=Full_Duplex_Master
PA7.Signal=SPI1_MOSI
PA8.Mode=I2C
PA8.Signal=I2C3_SCL
PA9.Mode=Activate_VBUS_FS
PA9.Signal=USB_OTG_HS_VBUS
PB0.Signal=ADCx_INP9
PB1.Signal=ADCx_INP5
PB10.GPIO_Speed=GPIO_SPEED_FREQ_HIGH
PB10.Mode=RGB565
PB10.Signal=LTDC_G4
PB11.GPIO_Label=LO_BASE_CLK
PB11.Signal=S_TIM2_CH4
PB12.GPIO_Label=HARDPWR_ERR
PB12.GPIO_ModeDefaultEXTI=GPIO_MODE_IT_RISING
PB12.GPIO_PuPd=GPIO_PULLDOWN
PB12.Signal=GPXTI12
PB13.GPIO_Label=RF_IN_PROTECT_CPU_SIG
PB13.Signal=GPIO_Output
PB14.Mode=SD_4_bits_Wide_bus
PB14.Signal=SDMMC2_D0
PB15.Mode=SD_4_bits_Wide_bus
PB15.Signal=SDMMC2_D1
PB2.GPIO_Pd=GPIO_PULLDOWN
PB2.Mode=INP
PB2.Signal=COMP1_INP
PB3.Mode=SD_4_bits_Wide_bus
PB3.Signal=SDMMC2_D2
PB4.Mode=Full_Duplex_Master
PB4.Signal=SPI6_MISO
PB5.Mode=RGB565
PB5.Signal=LTDC_B5
PB6.Mode=Asynchronous
PB6.Signal=LPUART1_TX
PB7.Mode=Asynchronous
PB7.Signal=LPUART1_RX
PB8.GPIO_Speed=GPIO_SPEED_FREQ_HIGH
PB8.Mode=RGB565
PB8.Signal=LTDC_B6
PB9.GPIO_Label=LIGHTNING_PROTECTION_A
PB9.Signal=GPIO_Output
PC0.GPIO_Speed=GPIO_SPEED_FREQ_HIGH
PC0.Mode=RGB565
PC0.Signal=LTDC_R5
PC1.GPIO_Speed=GPIO_SPEED_FREQ_HIGH
PC1.Mode=RGB565
PC1.Signal=LTDC_G5
PC10.Mode=Asynchronous
PC10.Signal=UART4_TX
PC11.Mode=Asynchronous
PC11.Signal=UART4_RX
PC12.GPIO_Speed=GPIO_SPEED_FREQ_HIGH
PC12.Mode=RGB565
PC12.Signal=LTDC_R6
PC13.GPIO_Label=KEY1_WKUP
PC13.Mode=WakeUp4
PC13.Signal=PWR_WKUP4
PC14-OSC32_IN.GPIO_Label=LPF6
PC14-OSC32_IN.Signal=GPIO_Output
PC15-OSC32_OUT.GPIO_Label=PTT_OUT
PC15-OSC32_OUT.Signal=GPIO_Output
PC2_C.Mode=IN0-Single-Ended
PC2_C.Signal=ADC2_INP0
PC3_C.Mode=IN1-Single-Ended
PC3_C.Signal=ADC2_INP1
PC4.Signal=ADCx_INP4
PC5.Signal=ADCx_INP8
PC6.GPIO_Speed=GPIO_SPEED_FREQ_HIGH
PC6.Mode=RGB565
PC6.Signal=LTDC_HSYNC
PC7.GPIO_Speed=GPIO_SPEED_FREQ_HIGH
PC7.Mode=RGB565
PC7.Signal=LTDC_G6
PC8.GPIO_Label=FAN1_PWM
PC8.Signal=S_TIM3_CH3
PC9.Mode=I2C
PC9.Signal=I2C3_SDA
PD0.Mode=FDCAN_Activate
PD0.Signal=FDCAN1_RX
PD1.Mode=FDCAN_Activate
PD1.Signal=FDCAN1_TX
PD10.GPIO_Speed=GPIO_SPEED_FREQ_HIGH
PD10.Mode=RGB565
PD10.Signal=LTDC_B3
PD11.Mode=SAI_A_MasterWithClock
PD11.Signal=SAI2_SD_A
PD12.Mode=SAI_A_MasterWithClock
PD12.Signal=SAI2_FS_A
PD13.Mode=SAI_A_MasterWithClock
PD13.Signal=SAI2_SCK_A
PD14.GPIO_Label=BL_PWM
PD14.Signal=S_TIM4_CH3
PD15.GPIO_Label=PUMP_PWM
PD15.Signal=S_TIM4_CH4
PD2.GPIO_Speed=GPIO_SPEED_FREQ_HIGH
PD2.Mode=RGB565
PD2.Signal=LTDC_B7
PD3.GPIO_Speed=GPIO_SPEED_FREQ_HIGH
PD3.Mode=RGB565
PD3.Signal=LTDC_G7
PD4.GPIO_Label=FAN1_SENSEX
PD4.GPIO_PuPd=GPIO_PULLUP
PD4.Signal=GPIO_Input
PD5.GPIO_Label=PUMP_SENSEX
PD5.GPIO_PuPd=GPIO_PULLUP
PD5.Signal=GPIO_Input
PD6.Mode=SD_4_bits_Wide_bus
PD6.Signal=SDMMC2_CK
PD7.Mode=SD_4_bits_Wide_bus
PD7.Signal=SDMMC2_CMD
PD8.GPIO_Label=CPU_READY
PD8.GPIO_PuPd=GPIO_NOPULL
PD8.Signal=GPIO_Output
PD9.GPIO_Label=LIGHTNING_PROTECTION_B
PD9.Signal=GPIO_Output
PE0.Mode=SAI_A_MasterWithClock
PE0.Signal=SAI2_MCLK_A
PE1.GPIO_Label=LPF1
PE1.Signal=GPIO_Output
PE10.GPIO_Label=TFT_DISP
PE10.Signal=GPIO_Output
PE11.Mode=RGB565
PE11.Signal=LTDC_G3
PE12.GPIO_Speed=GPIO_SPEED_FREQ_VERY_HIGH
PE12.Mode=ExternalOutput
PE12.Signal=COMP1_OUT
PE13.Mode=RGB565
PE13.Signal=LTDC_DE
PE14.GPIO_Speed=GPIO_SPEED_FREQ_HIGH
PE14.Mode=RGB565
PE14.Signal=LTDC_CLK
PE15.GPIO_Speed=GPIO_SPEED_FREQ_HIGH
PE15.Mode=RGB565
PE15.Signal=LTDC_R7
PE2.GPIO_Label=LPF2
PE2.Signal=GPIO_Output
PE3.GPIO_Label=LPF3
PE3.Signal=GPIO_Output
PE4.GPIO_Label=LPF4
PE4.Signal=GPIO_Output
PE5.GPIO_Label=LPF5
PE5.Signal=GPIO_Output
PE6.GPIO_Label=BUZZER
PE6.Signal=S_TIM15_CH2
PE7.GPIO_Label=ETR_FREQDET
PE7.Signal=S_TIM1_ETR
PE8.GPIO_Speed=GPIO_SPEED_FREQ_VERY_HIGH
PE8.Mode=ExternalOutput
PE8.Signal=COMP2_OUT
PE9.GPIO_Pd=GPIO_PULLDOWN
PE9.Mode=INP
PE9.Signal=COMP2_INP
PF0.Mode=I2C
PF0.Signal=I2C2_SDA
PF1.Mode=I2C
PF1.Signal=I2C2_SCL
PF10.Mode=O1_P1_CLK
PF10.Signal=OCTOSPIM_P1_CLK
PF11.Mode=SAI_B_SyncSlave
PF11.Signal=SAI2_SD_B
PF12.Mode=IN6-Single-Ended
PF12.Signal=ADC1_INP6
PF13.Mode=IN2-Single-Ended
PF13.Signal=ADC2_INP2
PF14.Mode=IN6-Single-Ended
PF14.Signal=ADC2_INP6
PF15.GPIO_Label=BACKUP_POWEREDX
PF15.GPIO_ModeDefaultEXTI=GPIO_MODE_IT_RISING_FALLING
PF15.GPIO_PuPd=GPIO_PULLUP
PF15.Signal=GPXTI15
PF2.GPIO_Label=CTouch_INTX
PF2.GPIO_PuPd=GPIO_PULLUP
PF2.Signal=GPXTI2
PF3.GPIO_Label=CTouch_RSTX
PF3.Signal=GPIO_Output
PF4.GPIO_Label=REAR_RESERVED1
PF4.Signal=GPIO_Output
PF5.GPIO_Label=PTT_INX
PF5.GPIO_ModeDefaultEXTI=GPIO_MODE_IT_RISING_FALLING
PF5.GPIO_PuPd=GPIO_PULLUP
PF5.Signal=GPXTI5
PF6.Mode=OCTOSPI1_IOL_Port1L
PF6.Signal=OCTOSPIM_P1_IO3
PF7.Mode=OCTOSPI1_IOL_Port1L
PF7.Signal=OCTOSPIM_P1_IO2
PF8.Mode=OCTOSPI1_IOL_Port1L
PF8.Signal=OCTOSPIM_P1_IO0
PF9.Mode=OCTOSPI1_IOL_Port1L
PF9.Signal=OCTOSPIM_P1_IO1
PG0.GPIO_Label=ALC_PWM_OUT
PG0.GPIO_Speed=GPIO_SPEED_FREQ_VERY_HIGH
PG0.Signal=GPIO_Output
PG1.GPIO_Label=CLEAR_FAULTX_OC
PG1.GPIO_ModeDefaultOutputPP=GPIO_MODE_OUTPUT_OD
PG1.GPIO_PuPd=GPIO_NOPULL
PG1.PinState=GPIO_PIN_SET
PG1.Signal=GPIO_Output
PG10.Mode=NSS_Signal_Hard_Output
PG10.Signal=SPI1_NSS
PG11.GPIO_Mode=GPIO_MODE_AF_PP
PG11.GPIO_Speed=GPIO_SPEED_FREQ_HIGH
PG11.Mode=Full_Duplex_Master
PG11.Signal=SPI1_SCK
PG12.Mode=SD_4_bits_Wide_bus
PG12.Signal=SDMMC2_D3
PG13.Mode=Full_Duplex_Master
PG13.Signal=SPI6_SCK
PG14.Mode=Full_Duplex_Master
PG14.Signal=SPI6_MOSI
PG15.GPIO_Label=SDMMC2_CD
PG15.GPIO_PuPd=GPIO_PULLUP
PG15.Signal=GPIO_Input
PG2.GPIO_Label=RF_BIAS_ON
PG2.Signal=GPIO_Output
PG3.GPIO_Label=RELAY2
PG3.Signal=GPIO_Output
PG4.GPIO_Label=RELAY1
PG4.Signal=GPIO_Output
PG5.GPIO_Label=MAIN_PSU_ON_SIG
PG5.Signal=GPIO_Output
PG6.Mode=OCTOSPI1_Port1_NCS
PG6.Signal=OCTOSPIM_P1_NCS
PG7.GPIO_Label=PWR_ON_SIG
PG7.Signal=GPIO_Output
PG8.Mode=NSS_Signal_Hard_Output
PG8.Signal=SPI6_NSS
PG9.GPIO_Mode=GPIO_MODE_AF_PP
PG9.GPIO_Speed=GPIO_SPEED_FREQ_HIGH
PG9.Mode=Full_Duplex_Master
PG9.Signal=SPI1_MISO
PH0-OSC_IN.Mode=HSE-External-Oscillator
PH0-OSC_IN.Signal=RCC_OSC_IN
PH1-OSC_OUT.Mode=HSE-External-Oscillator
PH1-OSC_OUT.Signal=RCC_OSC_OUT
PWR.AVDLevel=PWR_AVDLEVEL_2
PWR.PVDLevel=PWR_PVDLEVEL_4
ProjectManager.HeapSize=0x200
ProjectManager.StackSize=0x1000
ProjectManager.TargetToolchain=CMake
RCC.ADCFreq_Value=50000000
RCC.APB1Freq_Value=125000000
RCC.APB2Freq_Value=125000000
RCC.APB3Freq_Value=125000000
RCC.APB4Freq_Value=125000000
RCC.CDPPRE=RCC_APB3_DIV2
RCC.CDPPRE1=RCC_APB1_DIV2
RCC.CDPPRE2=RCC_APB2_DIV2
RCC.CortexFreq_Value=250000000
RCC.DIVM1=2
RCC.DIVM2=2
RCC.DIVM3=6
RCC.DIVN1=40
RCC.DIVN2=16
RCC.DIVN3=58
RCC.DIVP2=4
RCC.DIVP3=10
RCC.DIVQ2=8
RCC.DIVQ3=24
RCC.DIVR2=4
RCC.DIVR3=10
RCC.EnbaleCSS=false
RCC.FDCANCLockSelection=RCC_FDCANCLKSOURCE_PLL2
RCC.HCLKFreq_Value=250000000
RCC.HSE_VALUE=25000000
RCC.LPUART1CLockSelection=RCC_LPUART1CLKSOURCE_CSI
RCC.PLL1_VCI_Range-AdvancedSettings=RCC_PLL1VCIRANGE_0
RCC.PLL1_VCO_SEL-AdvancedSettings=RCC_PLL1VCOMEDIUM
RCC.PLL2FRACN=0
RCC.PLL2_VCI_Range-AdvancedSettings=RCC_PLL2VCIRANGE_0
RCC.PLL2_VCO_SEL-AdvancedSettings=RCC_PLL2VCOWIDE
RCC.PLL3FRACN=8048
RCC.PLLFRACN=0
RCC.PLLSourceVirtual=RCC_PLLSOURCE_HSE
RCC.SAI2ACLockSelection=RCC_SAI2ACLKSOURCE_PLL3
RCC.SAI2BCLockSelection=RCC_SAI2BCLKSOURCE_PLL3
RCC.SDMMC1CLockSelection=RCC_SDMMCCLKSOURCE_PLL2
RCC.SPI123CLockSelection=RCC_SPI123CLKSOURCE_PLL2
RCC.SRDPPRE=RCC_APB4_DIV2
RCC.SYSCLKFreq_VALUE=250000000
RCC.SYSCLKSource=RCC_SYSCLKSOURCE_PLLCLK
RCC.USART234578CLockSelection=RCC_USART234578CLKSOURCE_PLL3
RCC.USBCLockSelection=RCC_USBCLKSOURCE_HSI48
RCC.USBFreq_Value=48000000
SAI2.AudioFrequency-SAI_A_MasterWithClock=SAI_AUDIO_FREQUENCY_48K
SAI2.ErrorAudioFreq-SAI_A_MasterWithClock=0.0 %
SAI2.FIFOThreshold-SAI_A_MasterWithClock=SAI_FIFOTHRESHOLD_1QF
SAI2.InitProtocol-SAI_A_MasterWithClock=Enable
SAI2.InitProtocol-SAI_B_SyncSlave=Enable
SAI2.Instance-SAI_A_MasterWithClock=SAI$Index_Block_A
SAI2.Instance-SAI_B_SyncSlave=SAI$Index_Block_B
SAI2.MckOutput-SAI_A_MasterWithClock=SAI_MCK_OUTPUT_ENABLE
SAI2.OutputDrive-SAI_A_MasterWithClock=SAI_OUTPUTDRIVE_ENABLE
SAI2.RealAudioFreq-SAI_A_MasterWithClock=48.0 KHz
SAI2.TriState-SAI_B_SyncSlave=SAI_OUTPUT_RELEASED
SAI2.VirtualMode-SAI_A_MasterWithClock=VM_MASTER
SAI2.VirtualMode-SAI_B_SyncSlave=VM_SLAVE
SAI2.VirtualProtocol-SAI_A_BASIC=VM_BASIC_PROTOCOL
SAI2.VirtualProtocol-SAI_B_BASIC=VM_BASIC_PROTOCOL
SDMMC2.ClockPowerSave=SDMMC_CLOCK_POWER_SAVE_ENABLE
SDMMC2.TransceiverPresent=SDMMC_TRANSCEIVER_NOT_PRESENT
SH.ADCx_INP14.0=ADC1_INP14,IN14-Single-Ended
SH.ADCx_INP4.0=ADC1_INP4,IN4-Single-Ended
SH.ADCx_INP5.0=ADC1_INP5,IN5-Single-Ended
SH.ADCx_INP8.0=ADC1_INP8,IN8-Single-Ended
SH.ADCx_INP9.0=ADC1_INP9,IN9-Single-Ended
SH.S_TIM15_CH2.0=TIM15_CH2,PWM Generation2 CH2
SH.S_TIM1_ETR.0=TIM1_ETR,ClockSourceETR_Mode2
SH.S_TIM2_CH4.0=TIM2_CH4,PWM Generation4 CH4
SH.S_TIM3_CH3.0=TIM3_CH3,PWM Generation3 CH3
SH.S_TIM4_CH3.0=TIM4_CH3,PWM Generation3 CH3
SH.S_TIM4_CH4.0=TIM4_CH4,PWM Generation4 CH4
SPI1.BaudRatePrescaler=SPI_BAUDRATEPRESCALER_32
SPI1.CalculateBaudRate=1.5625 MBits/s
SPI1.DataSize=SPI_DATASIZE_8BIT
SPI1.Direction=SPI_DIRECTION_2LINES
SPI1.Mode=SPI_MODE_MASTER
SPI1.VirtualNSS=VM_NSSHARD
SPI1.VirtualType=VM_MASTER
SPI6.CalculateBaudRate=62.5 MBits/s
SPI6.Direction=SPI_DIRECTION_2LINES
SPI6.Mode=SPI_MODE_MASTER
SPI6.VirtualNSS=VM_NSSHARD
SPI6.VirtualType=VM_MASTER
TIM1.AutoReloadPreload=TIM_AUTORELOAD_PRELOAD_ENABLE
TIM1.ClockDivision=TIM_CLOCKDIVISION_DIV2
TIM1.ClockFilter=1
TIM1.Prescaler=31
TIM15.Channel-PWM\ Generation2\ CH2=TIM_CHANNEL_2
TIM15.Prescaler=15
TIM2.AutoReloadPreload=TIM_AUTORELOAD_PRELOAD_ENABLE
TIM2.Channel-Output\ Compare1\ No\ Output=TIM_CHANNEL_1
TIM2.Channel-Output\ Compare2\ No\ Output=TIM_CHANNEL_2
TIM2.Channel-PWM\ Generation4\ CH4=TIM_CHANNEL_4
TIM2.Period=624
TIM2.Prescaler=0
TIM2.TIM_MasterOutputTrigger=TIM_TRGO_UPDATE
TIM3.Channel-PWM\ Generation3\ CH3=TIM_CHANNEL_3
TIM3.Prescaler=3
TIM4.Channel-PWM\ Generation3\ CH3=TIM_CHANNEL_3
TIM4.Channel-PWM\ Generation4\ CH4=TIM_CHANNEL_4
TIM7.Period=999
TIM7.Prescaler=19
USB_DEVICE.CLASS_NAME_HS=CDC
USB_DEVICE.VirtualMode=Cdc
USB_DEVICE.VirtualModeHS=Cdc_HS
USB_OTG_HS.VirtualMode-Device_Only_FS=Device_Only_FS
USB_OTG_HS.dma_enable-Device_Only_FS=ENABLE
USB_OTG_HS.use_dedicated_ep1-Device_Only_FS=ENABLE
VP_ADC2_TempSens_Input.Mode=IN-TempSens
VP_COMP1_VS_DACOUT1.Mode=INM_DACOUT1
VP_COMP2_VS_DACOUT2.Mode=INM_DACOUT2
VP_DAC1_VS_DACI1.Mode=DAC_OUT1_Int
VP_DAC1_VS_DACI2.Mode=DAC_OUT2_Int
VP_DAC2_VS_DACI1.Mode=DAC_OUT1_Int
VP_DAC2_VS_DACI2.Mode=DAC_OUT2_Int
VP_DMA2D_VS_DMA2D.Mode=DMA2D_Activate
VP_DTS_VS-DTS.Mode=DTS
VP_FREERTOS_VS_CMSIS_V2.Mode=CMSIS_V2
VP_MEMORYMAP_VS_MEMORYMAP.Mode=CurAppReg
VP_OCTOSPI1_VS_quad.Mode=quad_mode
VP_PWR_VDDA.Mode=AVD
VP_PWR_V_PVD_IN.Mode=Mode_PVD_Int
VP_RCC_USB.Mode=USB_HS
VP_SAI2_VP_$IpInstance_SAIA_SAI_BASIC.Mode=SAI_A_BASIC
VP_SAI2_VP_$IpInstance_SAIB_SAI_BASIC.Mode=SAI_B_BASIC
VP_SYS_VS_tim17.Mode=TIM17
VP_TIM15_VS_ClockSourceINT.Mode=Internal
VP_TIM2_VS_ClockSourceINT.Mode=Internal
VP_TIM2_VS_no_output1.Mode=Output Compare1 No Output
VP_TIM2_VS_no_output2.Mode=Output Compare2 No Output
VP_TIM3_VS_ClockSourceINT.Mode=Internal
VP_TIM4_VS_ClockSourceINT.Mode=Internal
VP_TIM5_VS_ClockSourceINT.Mode=Internal
VP_TIM7_VS_ClockSourceINT.Mode=Enable_Timer
VP_USB_DEVICE_VS_USB_DEVICE_CDC_HS.Mode=CDC_HS
VREF+.Mode=InternalMode
VREF+.Signal=VREFBUF_OUT
board=custom

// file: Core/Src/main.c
/* USER CODE BEGIN Header */
/**
  ******************************************************************************
  * @file           : main.c
  * @brief          : Main program body
  ******************************************************************************
  * @attention
  *
  * Copyright (c) 2026 STMicroelectronics.
  * All rights reserved.
  *
  * This software is licensed under terms that can be found in the LICENSE file
  * in the root directory of this software component.
  * If no LICENSE file comes with this software, it is provided AS-IS.
  *
  ******************************************************************************
  */
/* USER CODE END Header */
#include "main.h"
#include "FreeRTOS.h"
#include "cmsis_os2.h"
#include "adc.h"
#include "bdma2.h"
#include "comp.h"
#include "dac.h"
#include "dma.h"
#include "dma2d.h"
#include "dts.h"
#include "fdcan.h"
#include "i2c.h"
#include "usart.h"
#include "ltdc.h"
#include "sai.h"
#include "sdmmc.h"
#include "spi.h"
#include "tim.h"
#include "usb_device.h"
#include "gpio.h"

/* USER CODE BEGIN Includes */
#include "boot.h"
#include "config.h"
#include "user_adc.h"
#include "power_control.h"
#include "protection.h"
#include "touch.h"
#include "gui.h"
#include "app_tasks.h"
/* USER CODE END Includes */

void SystemClock_Config(void);
void PeriphCommonClock_Config(void);
static void MPU_Config(void);
void MX_FREERTOS_Init(void);

int main(void)
{

  /* MPU Configuration--------------------------------------------------------*/
  MPU_Config();

  /* Enable the CPU Cache */

  /* Enable I-Cache---------------------------------------------------------*/
  SCB_EnableICache();

  /* Enable D-Cache---------------------------------------------------------*/
  SCB_EnableDCache();

  /* MCU Configuration--------------------------------------------------------*/

  /* Reset of all peripherals, Initializes the Flash interface and the Systick. */
  HAL_Init();

  /* Configure the system clock */
  SystemClock_Config();

  /* Configure the peripherals common clocks */
  PeriphCommonClock_Config();

  /* Initialize all configured peripherals */
  MX_GPIO_Init();
  MX_DMA_Init();
  MX_BDMA2_Init();
  MX_ADC1_Init();
  MX_ADC2_Init();
  MX_COMP1_Init();
  MX_COMP2_Init();
  MX_DAC1_Init();
  MX_DAC2_Init();
  MX_DMA2D_Init();
  MX_DTS_Init();
  MX_FDCAN1_Init();
  MX_I2C3_Init();
  MX_LPUART1_UART_Init();
  MX_LTDC_Init();
  MX_SPI1_Init();
  MX_TIM1_Init();
  MX_TIM2_Init();
  MX_TIM3_Init();
  MX_TIM5_Init();
  MX_TIM7_Init();
  MX_TIM15_Init();
  MX_I2C2_Init();
  MX_SDMMC2_SD_Init();
  MX_UART4_Init();
  MX_SAI2_Init();
  MX_TIM4_Init();
  MX_SPI6_Init();
  /* USER CODE BEGIN 2 */
  /* =========================================================================
   *  BOOT SEQUENCE (design spec 2026-10-14)
   *
   *  Step 0 (hardware defaults, before main): RF_BIAS PG2 = LOW,
   *         PWR_ON PG7 = LOW, REAR_RESERVED1 PF4 = HIGH.  Nothing
   *         transmits because the ADC / COMP / protection chain is not
   *         armed yet and g_ptt_ready is still false.
   *
   *  Everything below runs single-threaded - osKernelStart() has NOT
   *  been called - so no RTOS primitive (mutex, queue) may be used here.
   *  That is why config_lock() is deliberately absent below.
   * ====================================================================== */

  /* --- Step 1: pin the safety pins and blank the panel -------------- */
  /* Explicit, not relying on the reset state: RF path de-energised,
   * REAR_RESERVED1 held high, BL_PWM forced to 0 % so the operator
   * never sees a half-drawn screen while we boot. */
  boot_gpio_safe_state();

  /* --- Step 2: load (or rebuild) the persistent config ---------------- */
  bool have_valid_config = config_init();

  /* --- Step 3: probe the touch controller ------------------------------ */
  /* GT911 on I2C3 first, then NS2009 on I2C2; 100 ms per transaction.
   * Single-threaded, so the probe cannot collide with anything. */
  touch_init();

  /* Decide whether the touch driver needs calibration:
   *   - config_init() said "no valid record" -> we just reset to
   *     defaults -> the touch transform is the identity -> prompt.
   *   - a valid record was loaded but its touch transform is still the
   *     identity (operator never finished) -> prompt.
   *   - otherwise -> straight to the main screen. */
  g_calibration_required = !have_valid_config || config_touch_needs_calibration();
  g_touch_calibrated     = !g_calibration_required;

  /* --- Step 4: push the config's protection limits into the hardware - */
  /* AWD1/AWD2/AWD3 thresholds plus the two COMP DAC references.  This
   * MUST happen before the kernel starts: MX_COMP1/2_Init() already
   * armed the comparator interrupts, and a DAC reference of 0 would let
   * noise on the compared inputs latch a protection fault before the
   * operator ever sees the screen. */
  boot_apply_thresholds((int)BAND_15M_10M);

  /* --- Enable the two comparators ------------------------------------ */
  /* MX_COMPx_Init() only configures the peripheral; without this the
   * comparators stay disabled and HAL_COMP_TriggerCallback() would never
   * fire, i.e. the COMP1 overdrive and COMP2 over-current protections
   * would be dead code.  Started only after the DAC references above are
   * in place, so the very first comparison already uses the configured
   * threshold instead of the DAC's power-on value of 0 V. */
  if (HAL_COMP_Start_IT(&hcomp1) != HAL_OK) {
    Error_Handler();
  }
  if (HAL_COMP_Start_IT(&hcomp2) != HAL_OK) {
    Error_Handler();
  }

  /* --- Step 5: USB device bring-up (moved out of the deleted defaultTask) - */
  /* MX_USB_DEVICE_Init() is safe to call here: it does not depend on
   * FreeRTOS primitives, only registers the USB device descriptors and
   * starts the OTG_FS peripheral.  USB interrupt handlers stay dormant
   * until the NVIC is globally enabled (which happens at the first
   * context switch inside osKernelStart()), so no race exists.
   *
   * Previously this lived in freertos.c's defaultTask, which was a 512 B
   * idle task whose only job was to call MX_USB_DEVICE_Init() once and
   * then spin on osDelay(1).  Folding that one call into the boot
   * sequence retires the task and reclaims 512 B of stack + its TCB. */
  MX_USB_DEVICE_Init();

  /* --- Step 6: hand over to the scheduler (below) --------------------- */
  /* From here on g_gui_ready / g_ptt_ready take over: the GUI task opens
   * the backlight after its first repaint, and app_adc_task raises
   * g_ptt_ready once the IM zero-offset calibration has finished.  Until
   * both are true, power_control refuses every PTT request. */
  /* USER CODE END 2 */

  /* Init scheduler */
  osKernelInitialize();  /* Call init function for freertos objects (in cmsis_os2.c) */
  MX_FREERTOS_Init();

  /* Start scheduler */
  osKernelStart();

  /* We should never get here as control is now taken by the scheduler */

  /* Infinite loop */
  while (1)
  {

  }
}

void SystemClock_Config(void)
{
  RCC_OscInitTypeDef RCC_OscInitStruct = {0};
  RCC_ClkInitTypeDef RCC_ClkInitStruct = {0};
  RCC_CRSInitTypeDef RCC_CRSInitStruct = {0};

  /*AXI clock gating */
  RCC->CKGAENR = 0xE003FFFF;

  /** Supply configuration update enable
  */
  HAL_PWREx_ConfigSupply(PWR_LDO_SUPPLY);

  /** Configure the main internal regulator output voltage
  */
  __HAL_PWR_VOLTAGESCALING_CONFIG(PWR_REGULATOR_VOLTAGE_SCALE0);

  while(!__HAL_PWR_GET_FLAG(PWR_FLAG_VOSRDY)) {}

  /** Initializes the RCC Oscillators according to the specified parameters
  * in the RCC_OscInitTypeDef structure.
  */
  RCC_OscInitStruct.OscillatorType = RCC_OSCILLATORTYPE_HSI48|RCC_OSCILLATORTYPE_CSI
                              |RCC_OSCILLATORTYPE_LSI|RCC_OSCILLATORTYPE_HSE;
  RCC_OscInitStruct.HSEState = RCC_HSE_ON;
  RCC_OscInitStruct.LSIState = RCC_LSI_ON;
  RCC_OscInitStruct.HSI48State = RCC_HSI48_ON;
  RCC_OscInitStruct.CSIState = RCC_CSI_ON;
  RCC_OscInitStruct.CSICalibrationValue = 16;
  RCC_OscInitStruct.PLL.PLLState = RCC_PLL_ON;
  RCC_OscInitStruct.PLL.PLLSource = RCC_PLLSOURCE_HSE;
  RCC_OscInitStruct.PLL.PLLM = 2;
  RCC_OscInitStruct.PLL.PLLN = 40;
  RCC_OscInitStruct.PLL.PLLP = 2;
  RCC_OscInitStruct.PLL.PLLQ = 2;
  RCC_OscInitStruct.PLL.PLLR = 2;
  RCC_OscInitStruct.PLL.PLLRGE = RCC_PLL1VCIRANGE_3;
  RCC_OscInitStruct.PLL.PLLVCOSEL = RCC_PLL1VCOWIDE;
  RCC_OscInitStruct.PLL.PLLFRACN = 0;
  if (HAL_RCC_OscConfig(&RCC_OscInitStruct) != HAL_OK)
  {
    Error_Handler();
  }

  /** Initializes the CPU, AHB and APB buses clocks
  */
  RCC_ClkInitStruct.ClockType = RCC_CLOCKTYPE_HCLK|RCC_CLOCKTYPE_SYSCLK
                              |RCC_CLOCKTYPE_PCLK1|RCC_CLOCKTYPE_PCLK2
                              |RCC_CLOCKTYPE_D3PCLK1|RCC_CLOCKTYPE_D1PCLK1;
  RCC_ClkInitStruct.SYSCLKSource = RCC_SYSCLKSOURCE_PLLCLK;
  RCC_ClkInitStruct.SYSCLKDivider = RCC_SYSCLK_DIV1;
  RCC_ClkInitStruct.AHBCLKDivider = RCC_HCLK_DIV1;
  RCC_ClkInitStruct.APB3CLKDivider = RCC_APB3_DIV2;
  RCC_ClkInitStruct.APB1CLKDivider = RCC_APB1_DIV2;
  RCC_ClkInitStruct.APB2CLKDivider = RCC_APB2_DIV2;
  RCC_ClkInitStruct.APB4CLKDivider = RCC_APB4_DIV2;

  if (HAL_RCC_ClockConfig(&RCC_ClkInitStruct, FLASH_LATENCY_5) != HAL_OK)
  {
    Error_Handler();
  }

  /** Enable the SYSCFG APB clock
  */
  __HAL_RCC_CRS_CLK_ENABLE();

  /** Configures CRS
  */
  RCC_CRSInitStruct.Prescaler = RCC_CRS_SYNC_DIV1;
  RCC_CRSInitStruct.Source = RCC_CRS_SYNC_SOURCE_USB2;
  RCC_CRSInitStruct.Polarity = RCC_CRS_SYNC_POLARITY_RISING;
  RCC_CRSInitStruct.ReloadValue = __HAL_RCC_CRS_RELOADVALUE_CALCULATE(48000000,1000);
  RCC_CRSInitStruct.ErrorLimitValue = 34;
  RCC_CRSInitStruct.HSI48CalibrationValue = 32;

  HAL_RCCEx_CRSConfig(&RCC_CRSInitStruct);
}

void PeriphCommonClock_Config(void)
{
  RCC_PeriphCLKInitTypeDef PeriphClkInitStruct = {0};

  /** Initializes the peripherals clock
  */
  PeriphClkInitStruct.PeriphClockSelection = RCC_PERIPHCLK_ADC|RCC_PERIPHCLK_SDMMC
                              |RCC_PERIPHCLK_SAI2A|RCC_PERIPHCLK_SAI2B
                              |RCC_PERIPHCLK_SPI1|RCC_PERIPHCLK_FDCAN
                              |RCC_PERIPHCLK_UART4|RCC_PERIPHCLK_LTDC;
  PeriphClkInitStruct.PLL2.PLL2M = 2;
  PeriphClkInitStruct.PLL2.PLL2N = 16;
  PeriphClkInitStruct.PLL2.PLL2P = 4;
  PeriphClkInitStruct.PLL2.PLL2Q = 8;
  PeriphClkInitStruct.PLL2.PLL2R = 4;
  PeriphClkInitStruct.PLL2.PLL2RGE = RCC_PLL2VCIRANGE_3;
  PeriphClkInitStruct.PLL2.PLL2VCOSEL = RCC_PLL2VCOWIDE;
  PeriphClkInitStruct.PLL2.PLL2FRACN = 0;
  PeriphClkInitStruct.PLL3.PLL3M = 6;
  PeriphClkInitStruct.PLL3.PLL3N = 58;
  PeriphClkInitStruct.PLL3.PLL3P = 10;
  PeriphClkInitStruct.PLL3.PLL3Q = 24;
  PeriphClkInitStruct.PLL3.PLL3R = 10;
  PeriphClkInitStruct.PLL3.PLL3RGE = RCC_PLL3VCIRANGE_2;
  PeriphClkInitStruct.PLL3.PLL3VCOSEL = RCC_PLL3VCOWIDE;
  PeriphClkInitStruct.PLL3.PLL3FRACN = 8048;
  PeriphClkInitStruct.SdmmcClockSelection = RCC_SDMMCCLKSOURCE_PLL2;
  PeriphClkInitStruct.Sai2BClockSelection = RCC_SAI2BCLKSOURCE_PLL3;
  PeriphClkInitStruct.Sai2AClockSelection = RCC_SAI2ACLKSOURCE_PLL3;
  PeriphClkInitStruct.Spi123ClockSelection = RCC_SPI123CLKSOURCE_PLL2;
  PeriphClkInitStruct.FdcanClockSelection = RCC_FDCANCLKSOURCE_PLL2;
  PeriphClkInitStruct.Usart234578ClockSelection = RCC_USART234578CLKSOURCE_PLL3;
  PeriphClkInitStruct.AdcClockSelection = RCC_ADCCLKSOURCE_PLL2;
  if (HAL_RCCEx_PeriphCLKConfig(&PeriphClkInitStruct) != HAL_OK)
  {
    Error_Handler();
  }
}

/* USER CODE BEGIN 4 */

/**
  * @brief GPIO EXTI Callback for external interrupts
  * @param GPIO_Pin: Pin that triggered the interrupt
  * @retval None
  */
void HAL_GPIO_EXTI_Callback(uint16_t GPIO_Pin)
{
  if (GPIO_Pin == HARDPWR_ERR_Pin)
  {
    /* Hardware supply fault from the PSU (PB12, EXTI rising edge). */
    protection_hardpwr_err_isr();
  }
  else if (GPIO_Pin == PTT_INX_Pin)
  {
    /* Foot pedal / PTT key edge (PF5, EXTI5, active low). */
    power_control_ptt_isr();
  }
}

/**
  * @brief DMA half complete callback (for ADC double buffering)
  * @param hdma: DMA handle
  * @retval None
  */
void HAL_ADC_ConvHalfCpltCallback(ADC_HandleTypeDef* hadc)
{
  /* User can add code here if needed */
}

/**
  * @brief DMA complete callback
  * @param hadc ADC handle
  * @retval None
  */
void HAL_ADC_ConvCpltCallback(ADC_HandleTypeDef* hadc)
{
  if (hadc->Instance == ADC1)
  {
    /* Publish the fresh regular-group results, then compare the channels
       that have no analog watchdog behind them (REV2 / FWD1 / FWD2).
       Runs in interrupt context: integer only, no FreeRTOS, no FPU. */
    adc_process();
    protection_check_adc1_dma();
  }
}

/**
  * @brief Injected conversion complete callback (ADC2: NTC + die temp)
  * @param hadc ADC handle
  * @retval None
  *
  * @details
  *  Reads the three JDR registers (JDR1=NTC core, JDR2=NTC aux,
  *  JDR3=internal temp sensor) and publishes them to the volatile
  *  buffers in user_adc.c.  Even though this callback fires at
  *  JEOS (because EOCSelection=ADC_EOC_SEQ_CONV), JDRx is updated
  *  per single conversion so the read order is rank 1/2/3
  *  regardless.  Reading must happen here - the task side can't,
  *  because task reading vs ISR writing would race without a lock.
  *
  *  Then runs the NTC over-temperature check.  Core NTC has no
  *  analog watchdog, so the over-temperature comparison lives here
  *  rather than in the 100 ms backstop.
  */
void HAL_ADCEx_InjectedConvCpltCallback(ADC_HandleTypeDef* hadc)
{
  if (hadc->Instance == ADC2) {
    /* Order matches user_adc.c's three volatile slots and the ioc
     * InjectedChannel rows:
     *   Rank 1 = ADC_CHANNEL_2          -> adc2_inj_ntc_core_raw
     *   Rank 2 = ADC_CHANNEL_6          -> adc2_inj_ntc_aux_raw
     *   Rank 3 = ADC_CHANNEL_TEMPSENSOR -> adc2_inj_tsense_raw
     *
     * HAL_ADCEx_InjectedGetValue() reads the JDRx register of the
     * rank argument (1-based) - same convention as the ioc fields. */
    adc2_inj_ntc_core_raw = HAL_ADCEx_InjectedGetValue(hadc, ADC_INJECTED_RANK_1);
    adc2_inj_ntc_aux_raw  = HAL_ADCEx_InjectedGetValue(hadc, ADC_INJECTED_RANK_2);
    adc2_inj_tsense_raw   = HAL_ADCEx_InjectedGetValue(hadc, ADC_INJECTED_RANK_3);
  }
  /* Core NTC has no analog watchdog, so the over-temperature comparison
     lives here rather than in the 100 ms backstop. */
  protection_check_ntc();
}

/* Analog watchdog interrupts.  These fire from ADC1_2_IRQHandler at main
   priority 0, so the shutdown happens before anything else can run. */

void HAL_ADC_LevelOutOfWindowCallback(ADC_HandleTypeDef* hadc)
{
  (void)hadc;
  protection_awd1_cb();     /* AWD1 -> CH4 RF input power  */
}

void HAL_ADCEx_LevelOutOfWindow2Callback(ADC_HandleTypeDef* hadc)
{
  (void)hadc;
  protection_awd2_cb();     /* AWD2 -> CH5 main current     */
}

void HAL_ADCEx_LevelOutOfWindow3Callback(ADC_HandleTypeDef* hadc)
{
  (void)hadc;
  protection_awd3_cb();     /* AWD3 -> CH6 coupler 1 reverse */
}

/**
  * @brief Comparator trigger callback.
  *
  * Fires from COMP_IRQHandler (main priority 0) via HAL_COMP_IRQHandler()
  * when either comparator's EXTI line fires.  The HAL provides this as a
  * __weak no-op, so without this override BOTH COMP protections are
  * silently dead: the interrupt reaches the HAL and then goes nowhere.
  *
  * COMP1 = RF input envelope overdrive (inverting input is DAC1 CH1,
  *         which boot_apply_thresholds() programs from
  *         g_config.band_rf_in_max_w).
  * COMP2 = main current over-current (inverting input is DAC1 CH2,
  *         programmed from g_config.band_im_max_mA).
  *
  * Both handlers run protection_trigger_locked(), which drops the relays,
  * the high-voltage rail and the PA bias synchronously - see the
  * concurrency note in protection.h.
  */
void HAL_COMP_TriggerCallback(COMP_HandleTypeDef* hcomp)
{
  if (hcomp == NULL)
  {
    return;
  }

  if (hcomp->Instance == COMP1)
  {
    protection_comp1_isr();
  }
  else if (hcomp->Instance == COMP2)
  {
    protection_comp2_isr();
  }
}

/* USER CODE END 4 */

 /* MPU Configuration */

void MPU_Config(void)
{
  MPU_Region_InitTypeDef MPU_InitStruct = {0};

  /* Disables the MPU */
  HAL_MPU_Disable();

  /** Initializes and configures the Region and the memory to be protected
  */
  MPU_InitStruct.Enable = MPU_REGION_ENABLE;
  MPU_InitStruct.Number = MPU_REGION_NUMBER0;
  MPU_InitStruct.BaseAddress = 0x08000000;
  MPU_InitStruct.Size = MPU_REGION_SIZE_256KB;
  MPU_InitStruct.SubRegionDisable = 0;
  MPU_InitStruct.TypeExtField = MPU_TEX_LEVEL0;
  MPU_InitStruct.AccessPermission = MPU_REGION_FULL_ACCESS;
  MPU_InitStruct.DisableExec = MPU_INSTRUCTION_ACCESS_ENABLE;
  MPU_InitStruct.IsShareable = MPU_ACCESS_NOT_SHAREABLE;
  MPU_InitStruct.IsCacheable = MPU_ACCESS_CACHEABLE;
  MPU_InitStruct.IsBufferable = MPU_ACCESS_BUFFERABLE;

  HAL_MPU_ConfigRegion(&MPU_InitStruct);

  /** Initializes and configures the Region and the memory to be protected
  */
  MPU_InitStruct.Number = MPU_REGION_NUMBER1;
  MPU_InitStruct.BaseAddress = 0x90000000;
  MPU_InitStruct.Size = MPU_REGION_SIZE_128MB;
  MPU_InitStruct.SubRegionDisable = 0x0;

  HAL_MPU_ConfigRegion(&MPU_InitStruct);

  /** Initializes and configures the Region and the memory to be protected
  */
  MPU_InitStruct.Number = MPU_REGION_NUMBER2;
  MPU_InitStruct.BaseAddress = 0x20000000;
  MPU_InitStruct.Size = MPU_REGION_SIZE_128KB;
  MPU_InitStruct.IsCacheable = MPU_ACCESS_NOT_CACHEABLE;
  MPU_InitStruct.IsBufferable = MPU_ACCESS_NOT_BUFFERABLE;

  HAL_MPU_ConfigRegion(&MPU_InitStruct);

  /** Initializes and configures the Region and the memory to be protected
  */
  MPU_InitStruct.Number = MPU_REGION_NUMBER3;
  MPU_InitStruct.BaseAddress = 0x24000000;
  MPU_InitStruct.Size = MPU_REGION_SIZE_1MB;
  MPU_InitStruct.IsCacheable = MPU_ACCESS_CACHEABLE;
  MPU_InitStruct.IsBufferable = MPU_ACCESS_BUFFERABLE;

  HAL_MPU_ConfigRegion(&MPU_InitStruct);

  /** Initializes and configures the Region and the memory to be protected
  */
  MPU_InitStruct.Number = MPU_REGION_NUMBER4;
  MPU_InitStruct.Size = MPU_REGION_SIZE_512KB;
  MPU_InitStruct.IsCacheable = MPU_ACCESS_NOT_CACHEABLE;
  MPU_InitStruct.IsBufferable = MPU_ACCESS_NOT_BUFFERABLE;

  HAL_MPU_ConfigRegion(&MPU_InitStruct);

  /** Initializes and configures the Region and the memory to be protected
  */
  MPU_InitStruct.Number = MPU_REGION_NUMBER5;
  MPU_InitStruct.BaseAddress = 0x30000000;
  MPU_InitStruct.Size = MPU_REGION_SIZE_128KB;
  MPU_InitStruct.IsCacheable = MPU_ACCESS_CACHEABLE;
  MPU_InitStruct.IsBufferable = MPU_ACCESS_BUFFERABLE;

  HAL_MPU_ConfigRegion(&MPU_InitStruct);

  /** Initializes and configures the Region and the memory to be protected
  */
  MPU_InitStruct.Number = MPU_REGION_NUMBER6;
  MPU_InitStruct.BaseAddress = 0x38000000;
  MPU_InitStruct.Size = MPU_REGION_SIZE_32KB;
  MPU_InitStruct.IsCacheable = MPU_ACCESS_NOT_CACHEABLE;
  MPU_InitStruct.IsBufferable = MPU_ACCESS_NOT_BUFFERABLE;

  HAL_MPU_ConfigRegion(&MPU_InitStruct);
  /* Enables the MPU */
  HAL_MPU_Enable(MPU_PRIVILEGED_DEFAULT);

}

void HAL_TIM_PeriodElapsedCallback(TIM_HandleTypeDef *htim)
{
  if (htim->Instance == TIM17)
  {
    HAL_IncTick();
  }
  /* USER CODE BEGIN Callback 1 */
  if (htim->Instance == TIM5)
  {
    /* TIM5 is the 15 ms break-before-make delay for the PTT relay
     * sequence; it is started/stopped entirely from power_control.c. */
    power_relay_timer_callback();
  }
  /* USER CODE END Callback 1 */
}

void Error_Handler(void)
{
  __disable_irq();
  while (1)
  {
  }
}

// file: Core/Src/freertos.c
/* USER CODE BEGIN Header */
/**
  ******************************************************************************
  * File Name          : freertos.c
  * Description        : Code for freertos applications
  ******************************************************************************
  * @attention
  *
  * Copyright (c) 2026 STMicroelectronics.
  * All rights reserved.
  *
  * This software is licensed under terms that can be found in the LICENSE file
  * in the root directory of this software component.
  * If no LICENSE file comes with this software, it is provided AS-IS.
  *
  ******************************************************************************
  */
/* USER CODE END Header */

#include "FreeRTOS.h"
#include "task.h"
#include "main.h"
#include "FreeRTOS.h"
#include "cmsis_os2.h"

void MX_FREERTOS_Init(void); /* (MISRA C 2004 rule 8.1) */

void MX_FREERTOS_Init(void) {

  /* USER CODE BEGIN RTOS_THREADS */
  /* The defaultTask that previously lived here (a 512 B idle task that
   * only called MX_USB_DEVICE_Init() and then osDelay(1)) was retired.
   * The USB init is now done in main.c just before osKernelInitialize()
   * - it has no RTOS dependencies, so the indirection through a task
   * was buying nothing but 512 B of stack + a TCB.  The real
   * application tasks (GUI/ADC/Comm/Monitor/Protect/Config) are still
   * created in app_tasks.c via app_tasks_create() - call that from
   * USER CODE BEGIN RTOS_THREADS below if it ever needs to be moved
   * here for CubeMX regen reasons. */
  /* USER CODE END RTOS_THREADS */

}
